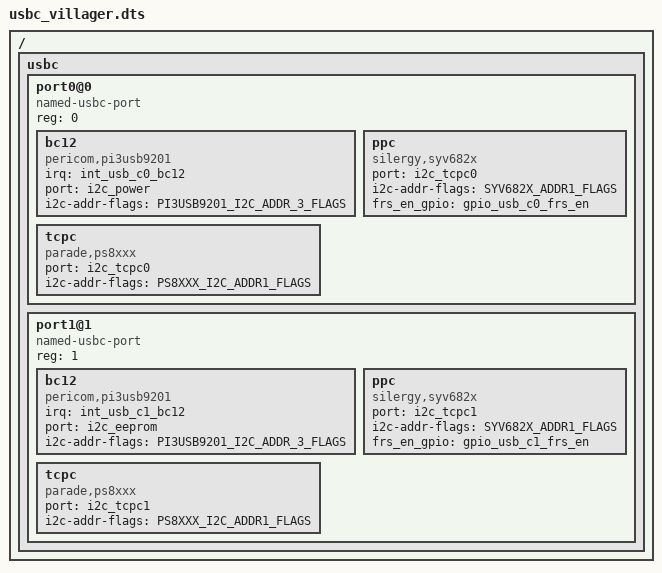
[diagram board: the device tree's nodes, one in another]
/* Copyright 2022 The Chromium OS Authors. All rights reserved.
 * Use of this source code is governed by a BSD-style license that can be
 * found in the LICENSE file.
 */

/ {
	usbc {
		#address-cells = <1>;
		#size-cells = <0>;

		port0@0 {
			compatible = "named-usbc-port";
			reg = <0>;
			bc12 {
				compatible = "pericom,pi3usb9201";
				status = "okay";
				irq = <&int_usb_c0_bc12>;
				port = <&i2c_power>;
				i2c-addr-flags = "PI3USB9201_I2C_ADDR_3_FLAGS";
			};
			ppc {
				compatible = "silergy,syv682x";
				status = "okay";
				port = <&i2c_tcpc0>;
				i2c-addr-flags = "SYV682X_ADDR1_FLAGS";
				frs_en_gpio = <&gpio_usb_c0_frs_en>;
			};
			tcpc {
				compatible = "parade,ps8xxx";
				status = "okay";
				port = <&i2c_tcpc0>;
				i2c-addr-flags = "PS8XXX_I2C_ADDR1_FLAGS";
			};
		};

		port1@1 {
			compatible = "named-usbc-port";
			reg = <1>;
			bc12 {
				compatible = "pericom,pi3usb9201";
				status = "okay";
				irq = <&int_usb_c1_bc12>;
				port = <&i2c_eeprom>;
				i2c-addr-flags = "PI3USB9201_I2C_ADDR_3_FLAGS";
			};
			ppc {
				compatible = "silergy,syv682x";
				status = "okay";
				port = <&i2c_tcpc1>;
				i2c-addr-flags = "SYV682X_ADDR1_FLAGS";
				frs_en_gpio = <&gpio_usb_c1_frs_en>;
			};
			tcpc {
				compatible = "parade,ps8xxx";
				status = "okay";
				port = <&i2c_tcpc1>;
				i2c-addr-flags = "PS8XXX_I2C_ADDR1_FLAGS";
			};
		};
	};
};
